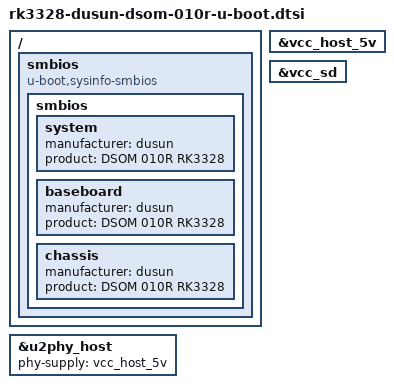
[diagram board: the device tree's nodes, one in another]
// SPDX-License-Identifier: GPL-2.0+

#include "rk3328-u-boot.dtsi"
#include "rk3328-sdram-ddr4-666.dtsi"

/ {

	smbios {
		compatible = "u-boot,sysinfo-smbios";

		smbios {
			system {
				manufacturer = "dusun";
				product = "DSOM 010R RK3328";
			};

			baseboard {
				manufacturer = "dusun";
				product = "DSOM 010R RK3328";
			};

			chassis {
				manufacturer = "dusun";
				product = "DSOM 010R RK3328";
			};
		};
	};
};

&u2phy_host {
	phy-supply = <&vcc_host_5v>;
};

&vcc_host_5v {
	/delete-property/ regulator-always-on;
	/delete-property/ regulator-boot-on;
};

&vcc_sd {
	bootph-pre-ram;
};

